VERSION ""

NS_ :

BS_:

BU_: Spacemouse Gr_v_ECU

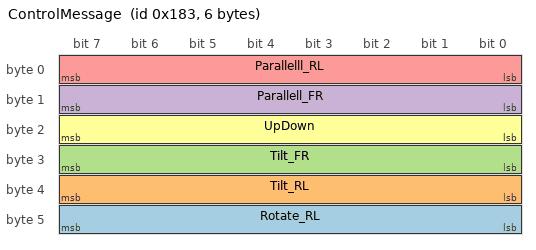
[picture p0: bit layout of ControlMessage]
BO_ 387 ControlMessage: 6 Spacemouse
 SG_ Rotate_RL : 40|8@1- (1,0) [0|0] "" Gr_v_ECU
 SG_ Tilt_RL : 32|8@1- (1,0) [0|0] "" Gr_v_ECU
 SG_ Tilt_FR : 24|8@1- (1,0) [0|0] "" Gr_v_ECU
 SG_ Parallell_FR : 8|8@1- (1,0) [0|0] "" Gr_v_ECU
 SG_ Parallelll_RL : 0|8@1- (1,0) [0|0] "" Gr_v_ECU
 SG_ UpDown : 16|8@1- (1,0) [0|0] "" Gr_v_ECU

BA_DEF_  "DBName" STRING ;
BA_DEF_  "BusType" STRING ;
BA_DEF_ BO_  "VFrameFormat" ENUM  "StandardCAN","ExtendedCAN","reserved","J1939PG";
BA_DEF_DEF_  "DBName" "can_signals";
BA_DEF_DEF_  "BusType" "CAN";
BA_ "VFrameFormat" BO_ 387 0;
